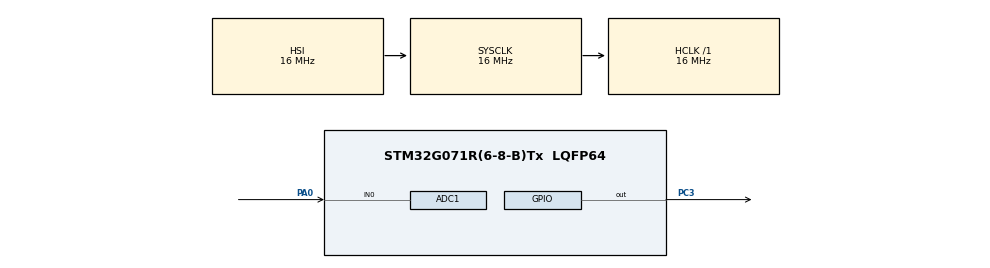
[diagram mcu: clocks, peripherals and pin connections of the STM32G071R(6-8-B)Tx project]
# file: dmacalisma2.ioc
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ADC1.Channel-0\#ChannelRegularConversion=ADC_CHANNEL_0
ADC1.Channel-1\#ChannelRegularConversion=ADC_CHANNEL_VREFINT
ADC1.ContinuousConvMode=ENABLE
ADC1.DMAContinuousRequests=ENABLE
ADC1.EOCSelection=ADC_EOC_SEQ_CONV
ADC1.NbrOfConversion=2
ADC1.NbrOfConversionFlag=1
ADC1.Rank-0\#ChannelRegularConversion=1
ADC1.Rank-1\#ChannelRegularConversion=2
ADC1.Resolution=ADC_RESOLUTION_12B
ADC1.SamplingTime-0\#ChannelRegularConversion=ADC_SAMPLINGTIME_COMMON_1
ADC1.SamplingTime-1\#ChannelRegularConversion=ADC_SAMPLINGTIME_COMMON_1
ADC1.SamplingTimeCommon1=ADC_SAMPLETIME_160CYCLES_5
ADC1.SelectedChannel=ADC_CHANNEL_0|ADC_CHANNEL_VREFINT
ADC1.master=1
Dma.ADC1.0.Direction=DMA_PERIPH_TO_MEMORY
Dma.ADC1.0.EventEnable=DISABLE
Dma.ADC1.0.Instance=DMA1_Channel1
Dma.ADC1.0.MemDataAlignment=DMA_MDATAALIGN_BYTE
Dma.ADC1.0.MemInc=DMA_MINC_ENABLE
Dma.ADC1.0.Mode=DMA_CIRCULAR
Dma.ADC1.0.PeriphDataAlignment=DMA_PDATAALIGN_BYTE
Dma.ADC1.0.PeriphInc=DMA_PINC_DISABLE
Dma.ADC1.0.Polarity=HAL_DMAMUX_REQ_GEN_RISING
Dma.ADC1.0.Priority=DMA_PRIORITY_LOW
Dma.ADC1.0.RequestNumber=1
Dma.ADC1.0.SignalID=NONE
Dma.ADC1.0.SyncEnable=DISABLE
Dma.ADC1.0.SyncPolarity=HAL_DMAMUX_SYNC_NO_EVENT
Dma.ADC1.0.SyncRequestNumber=1
Dma.ADC1.0.SyncSignalID=NONE
Dma.Request0=ADC1
Mcu.Family=STM32G0
Mcu.Name=STM32G071R(6-8-B)Tx
Mcu.Package=LQFP64
NVIC.DMA1_Channel1_IRQn=true\:0\:0\:false\:false\:true\:false\:true\:true
PA0.Mode=IN0
PA0.Signal=ADC1_IN0
PA13.Mode=Serial_Wire
PA13.Signal=SYS_SWDIO
PA14-BOOT0.Mode=Serial_Wire
PA14-BOOT0.Signal=SYS_SWCLK
PC3.Signal=GPIO_Output
PF0-OSC_IN\ (PF0).Mode=HSE-External-Oscillator
PF0-OSC_IN\ (PF0).Signal=RCC_OSC_IN
PF1-OSC_OUT\ (PF1).Mode=HSE-External-Oscillator
PF1-OSC_OUT\ (PF1).Signal=RCC_OSC_OUT
ProjectManager.HeapSize=0x200
ProjectManager.StackSize=0x400
ProjectManager.TargetToolchain=STM32CubeIDE
RCC.AHBFreq_Value=16000000
RCC.CortexFreq_Value=16000000
RCC.EXTERNAL_CLOCK_VALUE=48000
RCC.HCLKFreq_Value=16000000
RCC.HSE_VALUE=8000000
RCC.HSI_VALUE=16000000
RCC.LSE_VALUE=32768
RCC.SYSCLKFreq_VALUE=16000000
RCC.VCOOutputFreq_Value=128000000
VP_ADC1_Vref_Input.Mode=IN-Vrefint
board=custom

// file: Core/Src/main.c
/* USER CODE BEGIN Header */
/**
  ******************************************************************************
  * @file           : main.c
  * @brief          : Main program body
  ******************************************************************************
  * @attention
  *
  * Copyright (c) 2025 STMicroelectronics.
  * All rights reserved.
  *
  * This software is licensed under terms that can be found in the LICENSE file
  * in the root directory of this software component.
  * If no LICENSE file comes with this software, it is provided AS-IS.
  *
  ******************************************************************************
  */
/* USER CODE END Header */
#include "main.h"

ADC_HandleTypeDef hadc1;
DMA_HandleTypeDef hdma_adc1;

/* USER CODE BEGIN PV */
uint32_t  pData[1];
/* USER CODE END PV */

void SystemClock_Config(void);
static void MX_GPIO_Init(void);
static void MX_DMA_Init(void);
static void MX_ADC1_Init(void);

int main(void)
{

  /* MCU Configuration--------------------------------------------------------*/

  /* Reset of all peripherals, Initializes the Flash interface and the Systick. */
  HAL_Init();

  /* Configure the system clock */
  SystemClock_Config();

  /* Initialize all configured peripherals */
  MX_GPIO_Init();
  MX_DMA_Init();
  MX_ADC1_Init();
  /* USER CODE BEGIN 2 */
  HAL_ADC_Start_DMA(&hadc1, pData, 1);

  /* USER CODE END 2 */

  /* Infinite loop */
  while (1)
  {

  }
}

void SystemClock_Config(void)
{
  RCC_OscInitTypeDef RCC_OscInitStruct = {0};
  RCC_ClkInitTypeDef RCC_ClkInitStruct = {0};

  /** Configure the main internal regulator output voltage
  */
  HAL_PWREx_ControlVoltageScaling(PWR_REGULATOR_VOLTAGE_SCALE1);

  /** Initializes the RCC Oscillators according to the specified parameters
  * in the RCC_OscInitTypeDef structure.
  */
  RCC_OscInitStruct.OscillatorType = RCC_OSCILLATORTYPE_HSI;
  RCC_OscInitStruct.HSIState = RCC_HSI_ON;
  RCC_OscInitStruct.HSIDiv = RCC_HSI_DIV1;
  RCC_OscInitStruct.HSICalibrationValue = RCC_HSICALIBRATION_DEFAULT;
  RCC_OscInitStruct.PLL.PLLState = RCC_PLL_NONE;
  if (HAL_RCC_OscConfig(&RCC_OscInitStruct) != HAL_OK)
  {
    Error_Handler();
  }

  /** Initializes the CPU, AHB and APB buses clocks
  */
  RCC_ClkInitStruct.ClockType = RCC_CLOCKTYPE_HCLK|RCC_CLOCKTYPE_SYSCLK
                              |RCC_CLOCKTYPE_PCLK1;
  RCC_ClkInitStruct.SYSCLKSource = RCC_SYSCLKSOURCE_HSI;
  RCC_ClkInitStruct.AHBCLKDivider = RCC_SYSCLK_DIV1;
  RCC_ClkInitStruct.APB1CLKDivider = RCC_HCLK_DIV1;

  if (HAL_RCC_ClockConfig(&RCC_ClkInitStruct, FLASH_LATENCY_0) != HAL_OK)
  {
    Error_Handler();
  }
}

static void MX_ADC1_Init(void)
{

  ADC_ChannelConfTypeDef sConfig = {0};

  /** Configure the global features of the ADC (Clock, Resolution, Data Alignment and number of conversion)
  */
  hadc1.Instance = ADC1;
  hadc1.Init.ClockPrescaler = ADC_CLOCK_SYNC_PCLK_DIV2;
  hadc1.Init.Resolution = ADC_RESOLUTION_12B;
  hadc1.Init.DataAlign = ADC_DATAALIGN_RIGHT;
  hadc1.Init.ScanConvMode = ADC_SCAN_ENABLE;
  hadc1.Init.EOCSelection = ADC_EOC_SEQ_CONV;
  hadc1.Init.LowPowerAutoWait = DISABLE;
  hadc1.Init.LowPowerAutoPowerOff = DISABLE;
  hadc1.Init.ContinuousConvMode = ENABLE;
  hadc1.Init.NbrOfConversion = 2;
  hadc1.Init.ExternalTrigConv = ADC_SOFTWARE_START;
  hadc1.Init.ExternalTrigConvEdge = ADC_EXTERNALTRIGCONVEDGE_NONE;
  hadc1.Init.DMAContinuousRequests = ENABLE;
  hadc1.Init.Overrun = ADC_OVR_DATA_PRESERVED;
  hadc1.Init.SamplingTimeCommon1 = ADC_SAMPLETIME_160CYCLES_5;
  hadc1.Init.SamplingTimeCommon2 = ADC_SAMPLETIME_1CYCLE_5;
  hadc1.Init.OversamplingMode = DISABLE;
  hadc1.Init.TriggerFrequencyMode = ADC_TRIGGER_FREQ_HIGH;
  if (HAL_ADC_Init(&hadc1) != HAL_OK)
  {
    Error_Handler();
  }

  /** Configure Regular Channel
  */
  sConfig.Channel = ADC_CHANNEL_0;
  sConfig.Rank = ADC_REGULAR_RANK_1;
  sConfig.SamplingTime = ADC_SAMPLINGTIME_COMMON_1;
  if (HAL_ADC_ConfigChannel(&hadc1, &sConfig) != HAL_OK)
  {
    Error_Handler();
  }

  /** Configure Regular Channel
  */
  sConfig.Channel = ADC_CHANNEL_VREFINT;
  sConfig.Rank = ADC_REGULAR_RANK_2;
  if (HAL_ADC_ConfigChannel(&hadc1, &sConfig) != HAL_OK)
  {
    Error_Handler();
  }

}

static void MX_DMA_Init(void)
{

  /* DMA controller clock enable */
  __HAL_RCC_DMA1_CLK_ENABLE();

  /* DMA interrupt init */
  /* DMA1_Channel1_IRQn interrupt configuration */
  HAL_NVIC_SetPriority(DMA1_Channel1_IRQn, 0, 0);
  HAL_NVIC_EnableIRQ(DMA1_Channel1_IRQn);

}

static void MX_GPIO_Init(void)
{
  GPIO_InitTypeDef GPIO_InitStruct = {0};

  /* GPIO Ports Clock Enable */
  __HAL_RCC_GPIOF_CLK_ENABLE();
  __HAL_RCC_GPIOC_CLK_ENABLE();
  __HAL_RCC_GPIOA_CLK_ENABLE();

  /*Configure GPIO pin Output Level */
  HAL_GPIO_WritePin(GPIOC, GPIO_PIN_3, GPIO_PIN_RESET);

  /*Configure GPIO pin : PC3 */
  GPIO_InitStruct.Pin = GPIO_PIN_3;
  GPIO_InitStruct.Mode = GPIO_MODE_OUTPUT_PP;
  GPIO_InitStruct.Pull = GPIO_NOPULL;
  GPIO_InitStruct.Speed = GPIO_SPEED_FREQ_LOW;
  HAL_GPIO_Init(GPIOC, &GPIO_InitStruct);

}

void Error_Handler(void)
{
  __disable_irq();
  while (1)
  {
  }
}
